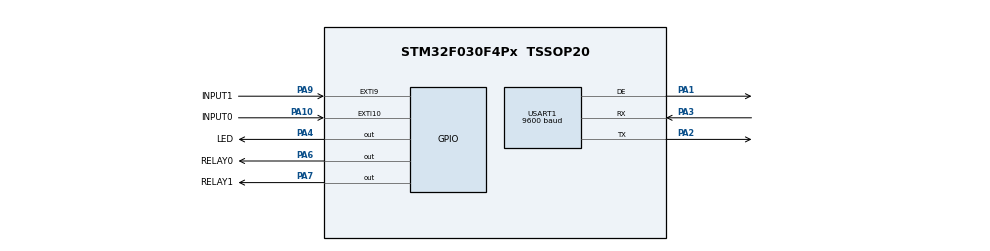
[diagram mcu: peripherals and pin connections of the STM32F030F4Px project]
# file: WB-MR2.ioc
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Mcu.Family=STM32F0
RCC.PLLSourceVirtual=RCC_PLLSOURCE_HSE
TIM3.CounterMode=TIM_COUNTERMODE_DOWN
VP_TIM3_VS_OPM.Mode=OPM_bit
PA10.GPIO_PuPd=GPIO_PULLUP
USART1.BaudRate=9600
PA9.GPIO_Label=INPUT1
PA6.GPIO_Label=RELAY0
PA9.GPIO_PuPd=GPIO_PULLUP
RCC.SYSCLKSource=RCC_SYSCLKSOURCE_HSE
ProjectManager.StackSize=0x400
USART1.VirtualMode-Asynchronous=VM_ASYNC
PA3.Mode=Asynchronous
PA13.Signal=SYS_SWDIO
USART1.StopBits=STOPBITS_2
ProjectManager.TargetToolchain=Makefile
TIM3.Period=65535
PA9.Signal=GPXTI9
RCC.PLLDivider=RCC_PREDIV_DIV2
PA1.Signal=USART1_DE
PF0-OSC_IN.Mode=HSE-External-Oscillator
board=custom
PA1.Mode=Hardware Flow Control (RS485)
PA14.Mode=Serial_Wire
TIM3.Prescaler=8
USART1.VirtualMode-Hardware\ Flow\ Control\ (RS485)=VM_ASYNC
PA10.GPIO_Label=INPUT0
PA13.Mode=Serial_Wire
Mcu.Name=STM32F030F4Px
PA2.Signal=USART1_TX
PA4.Signal=GPIO_Output
Mcu.Package=TSSOP20
PA6.Signal=GPIO_Output
PA7.GPIO_Label=RELAY1
PA10.GPIO_ModeDefaultEXTI=GPIO_MODE_IT_FALLING
PA10.Signal=GPXTI10
PA14.Signal=SYS_SWCLK
ProjectManager.HeapSize=0x200
PA9.GPIO_ModeDefaultEXTI=GPIO_MODE_IT_FALLING
PA2.Mode=Asynchronous
PF0-OSC_IN.Signal=RCC_OSC_IN
NVIC.USART1_IRQn=true\:0\:0\:false\:false\:true\:true\:true
PF1-OSC_OUT.Mode=HSE-External-Oscillator
PA4.GPIO_Label=LED
VP_TIM3_VS_ClockSourceINT.Mode=Internal
PF1-OSC_OUT.Signal=RCC_OSC_OUT
NVIC.EXTI4_15_IRQn=true\:0\:0\:false\:false\:true\:true\:true
PA3.Signal=USART1_RX
PA7.Signal=GPIO_Output

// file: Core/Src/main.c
/* USER CODE BEGIN Header */
/**
  ******************************************************************************
  * @file           : main.c
  * @brief          : Main program body
  ******************************************************************************
  * @attention
  *
  * <h2><center>&copy; Copyright (c) 2020 STMicroelectronics.
  * All rights reserved.</center></h2>
  *
  * This software component is licensed by ST under BSD 3-Clause license,
  * the "License"; You may not use this file except in compliance with the
  * License. You may obtain a copy of the License at:
  *                        opensource.org/licenses/BSD-3-Clause
  *
  ******************************************************************************
  */
/* USER CODE END Header */
#include "main.h"

/* USER CODE BEGIN Includes */
#include "application.h"

/* USER CODE END Includes */

/* USER CODE BEGIN PV */
const char model_str[7] = "WBMR2";

/* USER CODE END PV */

void SystemClock_Config(void);
static void MX_GPIO_Init(void);
static void MX_USART1_UART_Init(void);
static void MX_TIM3_Init(void);

int main(void)
{

  /* MCU Configuration--------------------------------------------------------*/

  /* Reset of all peripherals, Initializes the Flash interface and the Systick. */
  HAL_Init();

  /* Configure the system clock */
  SystemClock_Config();

  /* Initialize all configured peripherals */
  MX_GPIO_Init();
  MX_USART1_UART_Init();
  MX_TIM3_Init();
  /* USER CODE BEGIN 2 */
  setup();

  /* USER CODE END 2 */

  /* Infinite loop */
  /* USER CODE BEGIN WHILE */
  while (1)
  {
	loop();
    /* USER CODE END WHILE */

  }
}

void SystemClock_Config(void)
{
  LL_FLASH_SetLatency(LL_FLASH_LATENCY_0);
  while(LL_FLASH_GetLatency() != LL_FLASH_LATENCY_0)
  {
  }
  LL_RCC_HSE_Enable();

   /* Wait till HSE is ready */
  while(LL_RCC_HSE_IsReady() != 1)
  {

  }
  LL_RCC_SetAHBPrescaler(LL_RCC_SYSCLK_DIV_1);
  LL_RCC_SetAPB1Prescaler(LL_RCC_APB1_DIV_1);
  LL_RCC_SetSysClkSource(LL_RCC_SYS_CLKSOURCE_HSE);

   /* Wait till System clock is ready */
  while(LL_RCC_GetSysClkSource() != LL_RCC_SYS_CLKSOURCE_STATUS_HSE)
  {

  }
  LL_SetSystemCoreClock(8000000);

   /* Update the time base */
  if (HAL_InitTick (TICK_INT_PRIORITY) != HAL_OK)
  {
    Error_Handler();
  }
  LL_RCC_SetUSARTClockSource(LL_RCC_USART1_CLKSOURCE_PCLK1);
}

static void MX_TIM3_Init(void)
{

  LL_TIM_InitTypeDef TIM_InitStruct = {0};

  /* Peripheral clock enable */
  LL_APB1_GRP1_EnableClock(LL_APB1_GRP1_PERIPH_TIM3);

  TIM_InitStruct.Prescaler = 8;
  TIM_InitStruct.CounterMode = LL_TIM_COUNTERMODE_DOWN;
  TIM_InitStruct.Autoreload = 65535;
  TIM_InitStruct.ClockDivision = LL_TIM_CLOCKDIVISION_DIV1;
  LL_TIM_Init(TIM3, &TIM_InitStruct);
  LL_TIM_DisableARRPreload(TIM3);
  LL_TIM_SetClockSource(TIM3, LL_TIM_CLOCKSOURCE_INTERNAL);
  LL_TIM_SetOnePulseMode(TIM3, LL_TIM_ONEPULSEMODE_SINGLE);
  LL_TIM_SetTriggerOutput(TIM3, LL_TIM_TRGO_RESET);
  LL_TIM_DisableMasterSlaveMode(TIM3);

}

static void MX_USART1_UART_Init(void)
{

  LL_USART_InitTypeDef USART_InitStruct = {0};

  LL_GPIO_InitTypeDef GPIO_InitStruct = {0};

  /* Peripheral clock enable */
  LL_APB1_GRP2_EnableClock(LL_APB1_GRP2_PERIPH_USART1);

  LL_AHB1_GRP1_EnableClock(LL_AHB1_GRP1_PERIPH_GPIOA);
  /**USART1 GPIO Configuration
  PA1   ------> USART1_DE
  PA2   ------> USART1_TX
  PA3   ------> USART1_RX
  */
  GPIO_InitStruct.Pin = LL_GPIO_PIN_1;
  GPIO_InitStruct.Mode = LL_GPIO_MODE_ALTERNATE;
  GPIO_InitStruct.Speed = LL_GPIO_SPEED_FREQ_HIGH;
  GPIO_InitStruct.OutputType = LL_GPIO_OUTPUT_PUSHPULL;
  GPIO_InitStruct.Pull = LL_GPIO_PULL_NO;
  GPIO_InitStruct.Alternate = LL_GPIO_AF_1;
  LL_GPIO_Init(GPIOA, &GPIO_InitStruct);

  GPIO_InitStruct.Pin = LL_GPIO_PIN_2;
  GPIO_InitStruct.Mode = LL_GPIO_MODE_ALTERNATE;
  GPIO_InitStruct.Speed = LL_GPIO_SPEED_FREQ_HIGH;
  GPIO_InitStruct.OutputType = LL_GPIO_OUTPUT_PUSHPULL;
  GPIO_InitStruct.Pull = LL_GPIO_PULL_NO;
  GPIO_InitStruct.Alternate = LL_GPIO_AF_1;
  LL_GPIO_Init(GPIOA, &GPIO_InitStruct);

  GPIO_InitStruct.Pin = LL_GPIO_PIN_3;
  GPIO_InitStruct.Mode = LL_GPIO_MODE_ALTERNATE;
  GPIO_InitStruct.Speed = LL_GPIO_SPEED_FREQ_HIGH;
  GPIO_InitStruct.OutputType = LL_GPIO_OUTPUT_PUSHPULL;
  GPIO_InitStruct.Pull = LL_GPIO_PULL_NO;
  GPIO_InitStruct.Alternate = LL_GPIO_AF_1;
  LL_GPIO_Init(GPIOA, &GPIO_InitStruct);

  /* USART1 interrupt Init */
  NVIC_SetPriority(USART1_IRQn, 0);
  NVIC_EnableIRQ(USART1_IRQn);

  USART_InitStruct.BaudRate = 9600;
  USART_InitStruct.DataWidth = LL_USART_DATAWIDTH_8B;
  USART_InitStruct.StopBits = LL_USART_STOPBITS_2;
  USART_InitStruct.Parity = LL_USART_PARITY_NONE;
  USART_InitStruct.TransferDirection = LL_USART_DIRECTION_TX_RX;
  USART_InitStruct.HardwareFlowControl = LL_USART_HWCONTROL_NONE;
  USART_InitStruct.OverSampling = LL_USART_OVERSAMPLING_16;
  LL_USART_Init(USART1, &USART_InitStruct);
  LL_USART_EnableDEMode(USART1);
  LL_USART_SetDESignalPolarity(USART1, LL_USART_DE_POLARITY_HIGH);
  LL_USART_SetDEAssertionTime(USART1, 0);
  LL_USART_SetDEDeassertionTime(USART1, 0);
  LL_USART_ConfigAsyncMode(USART1);
  LL_USART_Enable(USART1);

}

static void MX_GPIO_Init(void)
{
  GPIO_InitTypeDef GPIO_InitStruct = {0};

  /* GPIO Ports Clock Enable */
  __HAL_RCC_GPIOF_CLK_ENABLE();
  __HAL_RCC_GPIOA_CLK_ENABLE();
  __HAL_RCC_GPIOB_CLK_ENABLE();

  /*Configure GPIO pin Output Level */
  HAL_GPIO_WritePin(GPIOA, LED_Pin|RELAY0_Pin|RELAY1_Pin, GPIO_PIN_RESET);

  /*Configure GPIO pins : PA0 PA5 */
  GPIO_InitStruct.Pin = GPIO_PIN_0|GPIO_PIN_5;
  GPIO_InitStruct.Mode = GPIO_MODE_ANALOG;
  GPIO_InitStruct.Pull = GPIO_NOPULL;
  HAL_GPIO_Init(GPIOA, &GPIO_InitStruct);

  /*Configure GPIO pins : LED_Pin RELAY0_Pin RELAY1_Pin */
  GPIO_InitStruct.Pin = LED_Pin|RELAY0_Pin|RELAY1_Pin;
  GPIO_InitStruct.Mode = GPIO_MODE_OUTPUT_PP;
  GPIO_InitStruct.Pull = GPIO_NOPULL;
  GPIO_InitStruct.Speed = GPIO_SPEED_FREQ_LOW;
  HAL_GPIO_Init(GPIOA, &GPIO_InitStruct);

  /*Configure GPIO pin : PB1 */
  GPIO_InitStruct.Pin = GPIO_PIN_1;
  GPIO_InitStruct.Mode = GPIO_MODE_ANALOG;
  GPIO_InitStruct.Pull = GPIO_NOPULL;
  HAL_GPIO_Init(GPIOB, &GPIO_InitStruct);

  /*Configure GPIO pins : INPUT1_Pin INPUT0_Pin */
  GPIO_InitStruct.Pin = INPUT1_Pin|INPUT0_Pin;
  GPIO_InitStruct.Mode = GPIO_MODE_IT_FALLING;
  GPIO_InitStruct.Pull = GPIO_PULLUP;
  HAL_GPIO_Init(GPIOA, &GPIO_InitStruct);

  /* EXTI interrupt init*/
  HAL_NVIC_SetPriority(EXTI4_15_IRQn, 0, 0);
  HAL_NVIC_EnableIRQ(EXTI4_15_IRQn);

}

void Error_Handler(void)
{
}

/************************ (C) COPYRIGHT STMicroelectronics *****END OF FILE****/
